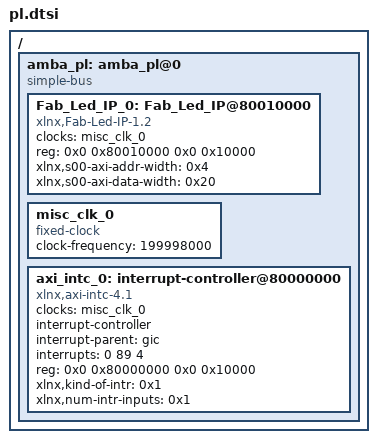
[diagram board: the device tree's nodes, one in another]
/*
 * CAUTION: This file is automatically generated by Xilinx.
 * Version: XSCT 2022.2
 * Today is: Thu Dec 28 10:48:24 2023
 */


/ {
	amba_pl: amba_pl@0 {
		#address-cells = <2>;
		#size-cells = <2>;
		compatible = "simple-bus";
		ranges ;
		Fab_Led_IP_0: Fab_Led_IP@80010000 {
			/* This is a place holder node for a custom IP, user may need to update the entries */
			clock-names = "s00_axi_aclk";
			clocks = <&misc_clk_0>;
			compatible = "xlnx,Fab-Led-IP-1.2";
			reg = <0x0 0x80010000 0x0 0x10000>;
			xlnx,s00-axi-addr-width = <0x4>;
			xlnx,s00-axi-data-width = <0x20>;
		};
		misc_clk_0: misc_clk_0 {
			#clock-cells = <0>;
			clock-frequency = <199998000>;
			compatible = "fixed-clock";
		};
		axi_intc_0: interrupt-controller@80000000 {
			#interrupt-cells = <2>;
			clock-names = "s_axi_aclk";
			clocks = <&misc_clk_0>;
			compatible = "xlnx,axi-intc-4.1", "xlnx,xps-intc-1.00.a";
			interrupt-controller ;
			interrupt-names = "irq";
			interrupt-parent = <&gic>;
			interrupts = <0 89 4>;
			reg = <0x0 0x80000000 0x0 0x10000>;
			xlnx,kind-of-intr = <0x1>;
			xlnx,num-intr-inputs = <0x1>;
		};
	};
};
